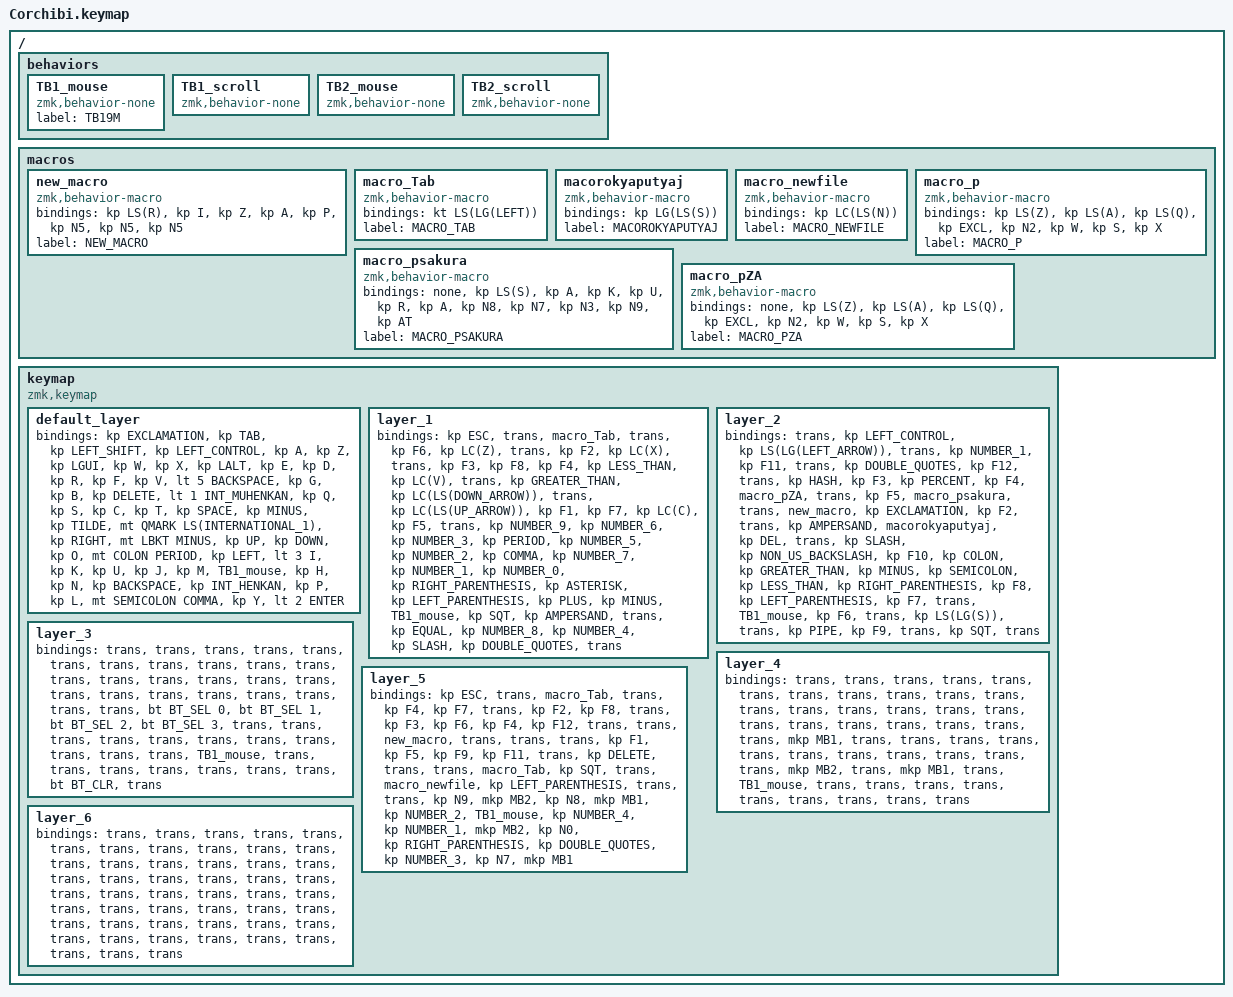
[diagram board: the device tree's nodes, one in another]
#include <dt-bindings/zmk/mouse.h>
#include <behaviors.dtsi>
#include <dt-bindings/zmk/bt.h>
#include <dt-bindings/zmk/keys.h>
#include <dt-bindings/zmk/pointing.h>

/ {
    behaviors {
        TB1_mouse: TB1_mouse {
            compatible = "zmk,behavior-none";
            label = "TB19M";
            #binding-cells = <0>;
        };

        TB1_scroll: TB1_scroll {
            compatible = "zmk,behavior-none";
            #binding-cells = <0>;
        };

        TB2_mouse: TB2_mouse {
            compatible = "zmk,behavior-none";
            #binding-cells = <0>;
        };

        TB2_scroll: TB2_scroll {
            compatible = "zmk,behavior-none";
            #binding-cells = <0>;
        };
    };

    macros {
        new_macro: new_macro {
            compatible = "zmk,behavior-macro";
            #binding-cells = <0>;
            bindings = <&kp LS(R) &kp I &kp Z &kp A &kp P &kp N5 &kp N5 &kp N5>;
            label = "NEW_MACRO";
        };

        macro_Tab: macro_Tab {
            compatible = "zmk,behavior-macro";
            #binding-cells = <0>;
            bindings = <&kt LS(LG(LEFT))>;
            label = "MACRO_TAB";
        };

        macorokyaputyaj: macorokyaputyaj {
            compatible = "zmk,behavior-macro";
            #binding-cells = <0>;
            bindings = <&kp LG(LS(S))>;
            label = "MACOROKYAPUTYAJ";
        };

        macro_newfile: macro_newfile {
            compatible = "zmk,behavior-macro";
            #binding-cells = <0>;
            bindings = <&kp LC(LS(N))>;
            label = "MACRO_NEWFILE";
        };

        macro_p: macro_p {
            compatible = "zmk,behavior-macro";
            #binding-cells = <0>;
            bindings = <&kp LS(Z) &kp LS(A) &kp LS(Q) &kp EXCL &kp N2 &kp W &kp S &kp X>;
            label = "MACRO_P";
        };

        macro_psakura: macro_psakura {
            compatible = "zmk,behavior-macro";
            #binding-cells = <0>;
            bindings = <&none &kp LS(S) &kp A &kp K &kp U &kp R &kp A &kp N8 &kp N7 &kp N3 &kp N9 &kp AT>;
            label = "MACRO_PSAKURA";
        };

        macro_pZA: macro_pZA {
            compatible = "zmk,behavior-macro";
            #binding-cells = <0>;
            bindings = <&none &kp LS(Z) &kp LS(A) &kp LS(Q) &kp EXCL &kp N2 &kp W &kp S &kp X>;
            label = "MACRO_PZA";
        };
    };

    keymap {
        compatible = "zmk,keymap";

        default_layer {
            bindings = <
&kp EXCLAMATION  &kp TAB  &kp LEFT_SHIFT  &kp LEFT_CONTROL  &kp A  &kp Z  &kp LGUI  &kp W  &kp X  &kp LALT  &kp E  &kp D  &kp R  &kp F  &kp V  &lt 5 BACKSPACE  &kp G  &kp B  &kp DELETE  &lt 1 INT_MUHENKAN  &kp Q  &kp S  &kp C  &kp T  &kp SPACE  &kp MINUS  &kp TILDE  &mt QMARK LS(INTERNATIONAL_1)  &kp RIGHT  &mt LBKT MINUS  &kp UP  &kp DOWN  &kp O  &mt COLON PERIOD  &kp LEFT  &lt 3 I  &kp K  &kp U  &kp J  &kp M  &TB1_mouse  &kp H  &kp N  &kp BACKSPACE  &kp INT_HENKAN  &kp P  &kp L  &mt SEMICOLON COMMA  &kp Y  &lt 2 ENTER
            >;
        };

        layer_1 {
            bindings = <
&kp ESC  &trans  &macro_Tab  &trans  &kp F6  &kp LC(Z)  &trans  &kp F2  &kp LC(X)  &trans  &kp F3  &kp F8  &kp F4  &kp LESS_THAN  &kp LC(V)  &trans  &kp GREATER_THAN  &kp LC(LS(DOWN_ARROW))  &trans  &kp LC(LS(UP_ARROW))  &kp F1  &kp F7  &kp LC(C)  &kp F5  &trans  &kp NUMBER_9  &kp NUMBER_6  &kp NUMBER_3  &kp PERIOD  &kp NUMBER_5  &kp NUMBER_2  &kp COMMA  &kp NUMBER_7  &kp NUMBER_1  &kp NUMBER_0  &kp RIGHT_PARENTHESIS  &kp ASTERISK  &kp LEFT_PARENTHESIS  &kp PLUS  &kp MINUS  &TB1_mouse  &kp SQT  &kp AMPERSAND  &trans  &kp EQUAL  &kp NUMBER_8  &kp NUMBER_4  &kp SLASH  &kp DOUBLE_QUOTES  &trans
            >;
        };

        layer_2 {
            bindings = <
&trans  &kp LEFT_CONTROL  &kp LS(LG(LEFT_ARROW))  &trans  &kp NUMBER_1  &kp F11  &trans  &kp DOUBLE_QUOTES  &kp F12  &trans  &kp HASH  &kp F3  &kp PERCENT  &kp F4  &macro_pZA  &trans  &kp F5  &macro_psakura  &trans  &new_macro  &kp EXCLAMATION  &kp F2  &trans  &kp AMPERSAND  &macorokyaputyaj  &kp DEL  &trans  &kp SLASH  &kp NON_US_BACKSLASH  &kp F10  &kp COLON  &kp GREATER_THAN  &kp MINUS  &kp SEMICOLON  &kp LESS_THAN  &kp RIGHT_PARENTHESIS  &kp F8  &kp LEFT_PARENTHESIS  &kp F7  &trans  &TB1_mouse  &kp F6  &trans  &kp LS(LG(S))  &trans  &kp PIPE  &kp F9  &trans  &kp SQT  &trans
            >;
        };

        layer_3 {
            bindings = <
&trans  &trans  &trans  &trans  &trans  &trans  &trans  &trans  &trans  &trans  &trans  &trans  &trans  &trans  &trans  &trans  &trans  &trans  &trans  &trans  &trans  &trans  &trans  &trans  &trans  &bt BT_SEL 0  &bt BT_SEL 1  &bt BT_SEL 2  &bt BT_SEL 3  &trans  &trans  &trans  &trans  &trans  &trans  &trans  &trans  &trans  &trans  &trans  &TB1_mouse  &trans  &trans  &trans  &trans  &trans  &trans  &trans  &bt BT_CLR  &trans
            >;
        };

        layer_4 {
            bindings = <
&trans  &trans  &trans  &trans  &trans  &trans  &trans  &trans  &trans  &trans  &trans  &trans  &trans  &trans  &trans  &trans  &trans  &trans  &trans  &trans  &trans  &trans  &trans  &trans  &mkp MB1  &trans  &trans  &trans  &trans  &trans  &trans  &trans  &trans  &trans  &trans  &trans  &mkp MB2  &trans  &mkp MB1  &trans  &TB1_mouse  &trans  &trans  &trans  &trans  &trans  &trans  &trans  &trans  &trans
            >;
        };

        layer_5 {
            bindings = <
&kp ESC  &trans  &macro_Tab  &trans  &kp F4  &kp F7  &trans  &kp F2  &kp F8  &trans  &kp F3  &kp F6  &kp F4  &kp F12  &trans  &trans  &new_macro  &trans  &trans  &trans  &kp F1  &kp F5  &kp F9  &kp F11  &trans  &kp DELETE  &trans  &trans  &macro_Tab  &kp SQT  &trans  &macro_newfile  &kp LEFT_PARENTHESIS  &trans  &trans  &kp N9  &mkp MB2  &kp N8  &mkp MB1  &kp NUMBER_2  &TB1_mouse  &kp NUMBER_4  &kp NUMBER_1  &mkp MB2  &kp N0  &kp RIGHT_PARENTHESIS  &kp DOUBLE_QUOTES  &kp NUMBER_3  &kp N7  &mkp MB1
            >;
        };

        layer_6 {
            bindings = <
&trans  &trans  &trans  &trans  &trans  &trans  &trans  &trans  &trans  &trans  &trans  &trans  &trans  &trans  &trans  &trans  &trans  &trans  &trans  &trans  &trans  &trans  &trans  &trans  &trans  &trans  &trans  &trans  &trans  &trans  &trans  &trans  &trans  &trans  &trans  &trans  &trans  &trans  &trans  &trans  &trans  &trans  &trans  &trans  &trans  &trans  &trans  &trans  &trans  &trans
            >;
        };
    };
};

// force trigger build
// apply DYA studio fixes
// fix central role and remove advertising config
// fix missing BLE central role
// slim down R config and fix endpoints
// bypass compiler strict warnings for auto_mouse_layer
// fix endpoint count by forcing central role
// remove invalid cmake configs
// remove undefined moNa2 configs
